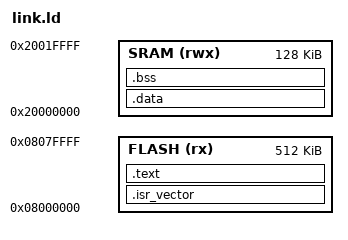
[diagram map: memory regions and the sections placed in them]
/*
 * link.ld — linker script for STM32G474 (DRAM-Phantom)
 *
 * Author: jayis1
 * License: GPL-2.0
 *
 * STM32G474CEU6: 512 KB flash @ 0x08000000, 128 KB SRAM @ 0x20000000.
 */

ENTRY(Reset_Handler)

MEMORY
{
    FLASH (rx)  : ORIGIN = 0x08000000, LENGTH = 512K
    SRAM  (rwx) : ORIGIN = 0x20000000, LENGTH = 128K
}

_estack = ORIGIN(SRAM) + LENGTH(SRAM);

SECTIONS
{
    .isr_vector :
    {
        KEEP(*(.isr_vector))
    } > FLASH

    .text :
    {
        *(.text*)
        *(.rodata*)
        KEEP(*(.init))
        KEEP(*(.fini))
        . = ALIGN(4);
        _etext = .;
    } > FLASH

    _sidata = LOADADDR(.data);
    .data : AT (_etext)
    {
        _sdata = .;
        *(.data*)
        . = ALIGN(4);
        _edata = .;
    } > SRAM

    .bss :
    {
        _sbss = .;
        *(.bss*)
        *(COMMON)
        . = ALIGN(4);
        _ebss = .;
    } > SRAM

    /DISCARD/ : { *(.ARM.exidx*) }
}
